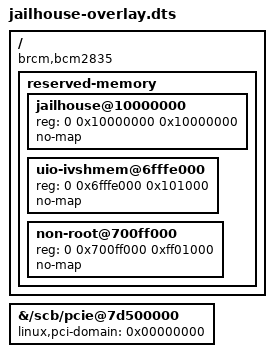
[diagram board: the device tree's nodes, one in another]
/dts-v1/;
/plugin/;
/ {
	compatible = "brcm,bcm2835";

	fragment@0 {
		target-path = "/";
		__overlay__ {
			reserved-memory {
				#address-cells = <2>;
				#size-cells = <1>;
				ranges;

				jailhouse@10000000 {
					reg = <0 0x10000000 0x10000000>;
					no-map;
				};

				/*
				 * 0x6fff e000 - 0x700f f000 for uio-ivshmem
				 * 0x700f f000 - 0x8000 0000 for non-root
				 */
				uio-ivshmem@6fffe000 {
					reg = <0 0x6fffe000 0x101000>;
					no-map;
				};
				non-root@700ff000 {
					reg = <0 0x700ff000 0xff01000>;
					no-map;
				};
			};
		};
	};

	fragment@1 {
		target-path = "/scb/pcie@7d500000";
		__overlay__ {
			linux,pci-domain = <0x00000000>;
		};
	};
};
